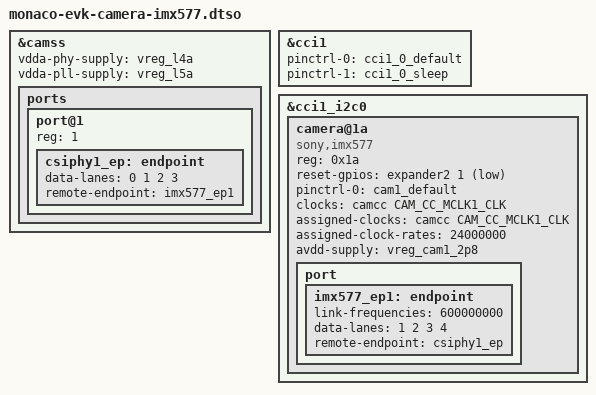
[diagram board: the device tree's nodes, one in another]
// SPDX-License-Identifier: BSD-3-Clause
/*
 * Copyright (c) Qualcomm Technologies, Inc. and/or its subsidiaries.
 */

/dts-v1/;
/plugin/;

#include <dt-bindings/clock/qcom,sa8775p-camcc.h>
#include <dt-bindings/gpio/gpio.h>

&camss {
	vdda-phy-supply = <&vreg_l4a>;
	vdda-pll-supply = <&vreg_l5a>;

	status = "okay";

	ports {
		#address-cells = <1>;
		#size-cells = <0>;

		port@1 {
			reg = <1>;

			csiphy1_ep: endpoint {
				data-lanes = <0 1 2 3>;
				remote-endpoint = <&imx577_ep1>;
			};
		};
	};
};

&cci1 {
	pinctrl-0 = <&cci1_0_default>;
	pinctrl-1 = <&cci1_0_sleep>;

	status = "okay";
};

&cci1_i2c0 {
	#address-cells = <1>;
	#size-cells = <0>;

	camera@1a {
		compatible = "sony,imx577";
		reg = <0x1a>;

		reset-gpios = <&expander2 1 GPIO_ACTIVE_LOW>;
		pinctrl-0 = <&cam1_default>;
		pinctrl-names = "default";

		clocks = <&camcc CAM_CC_MCLK1_CLK>;
		assigned-clocks = <&camcc CAM_CC_MCLK1_CLK>;
		assigned-clock-rates = <24000000>;

		avdd-supply = <&vreg_cam1_2p8>;

		port {
			imx577_ep1: endpoint {
				link-frequencies = /bits/ 64 <600000000>;
				data-lanes = <1 2 3 4>;
				remote-endpoint = <&csiphy1_ep>;
			};
		};
	};
};
